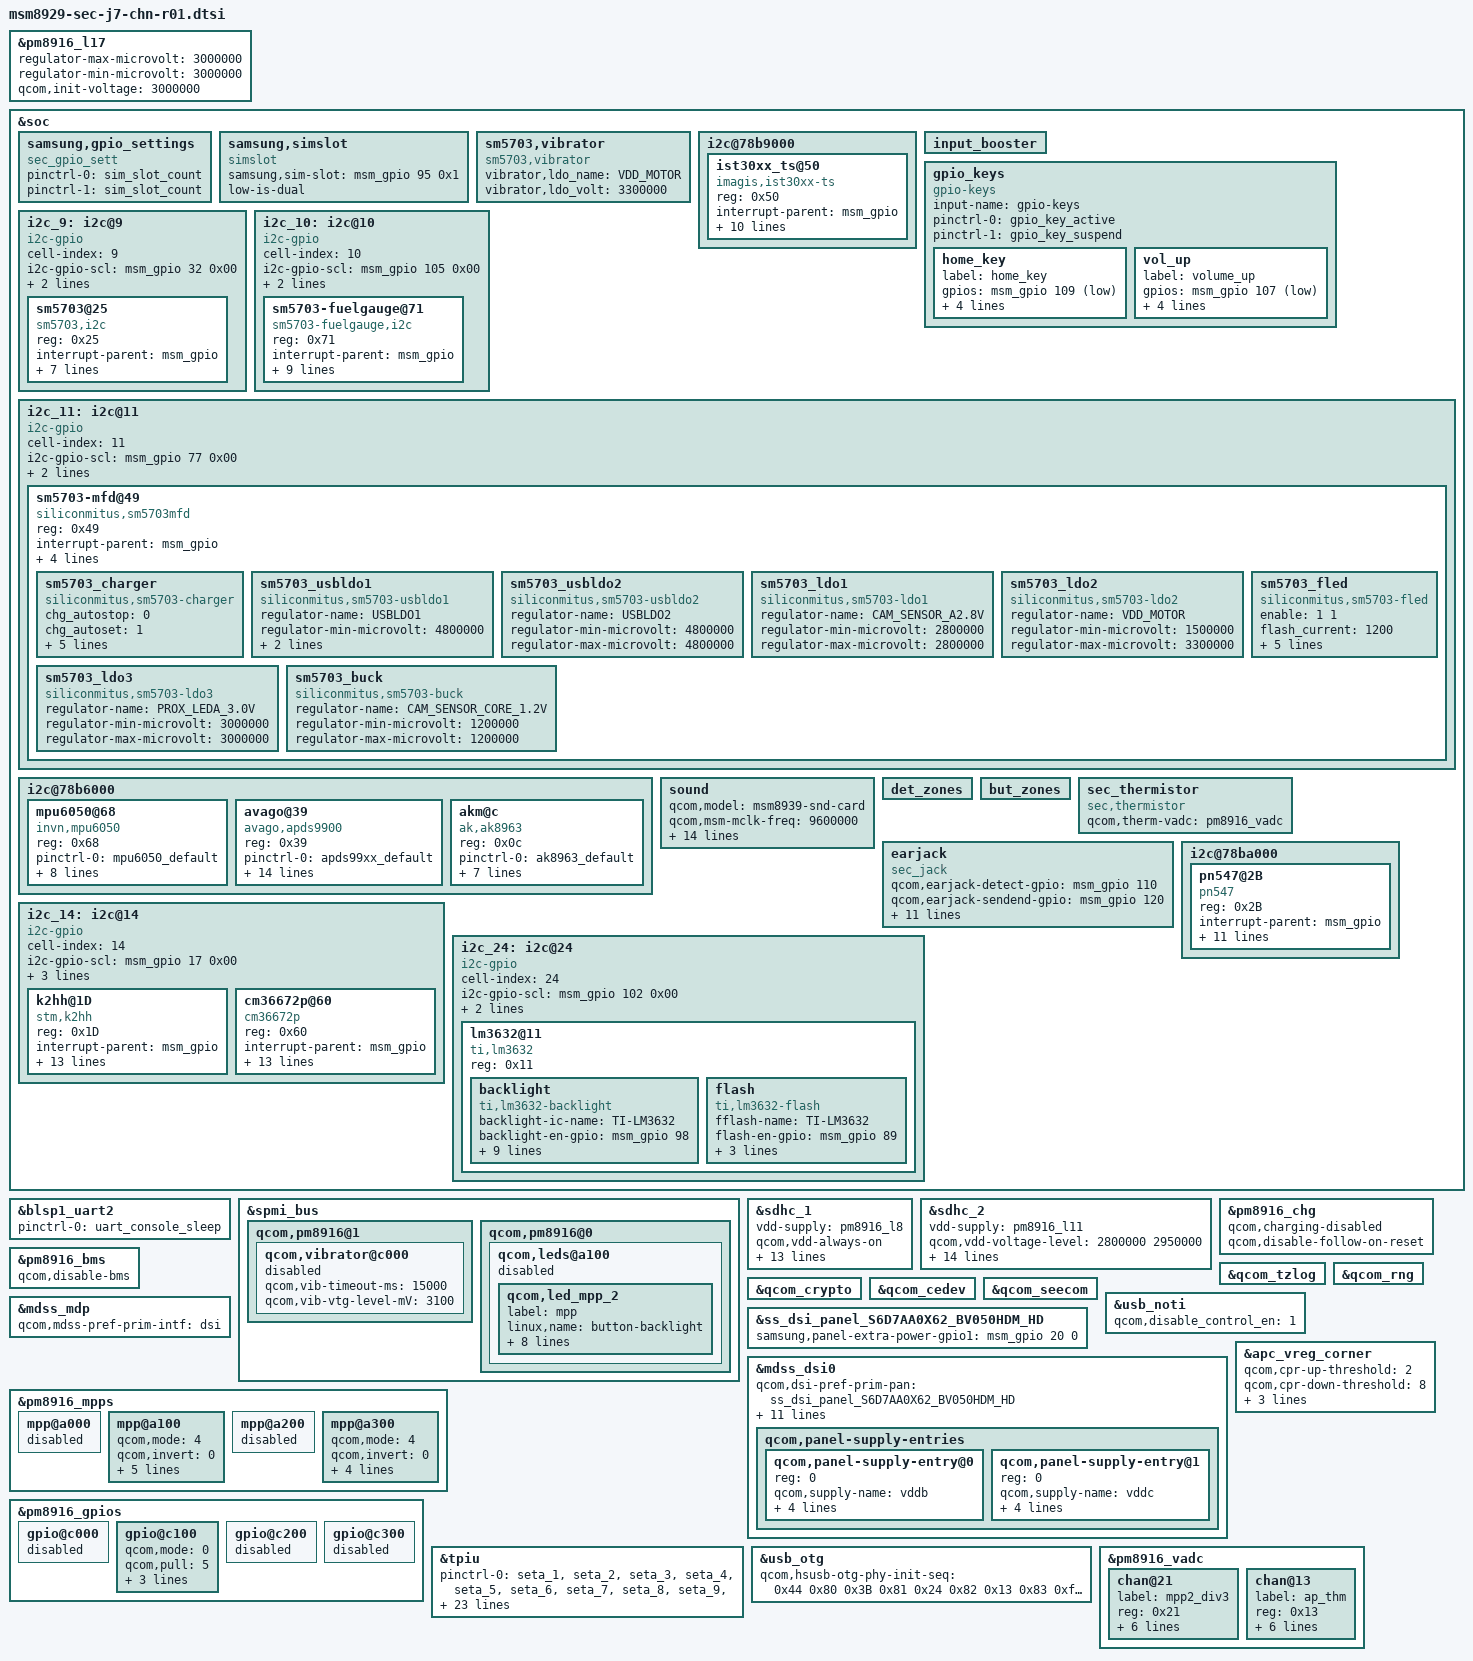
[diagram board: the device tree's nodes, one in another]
/*
 * Copyright (c) 2015, The Linux Foundation. All rights reserved.
 *
 * This program is free software; you can redistribute it and/or modify
 * it under the terms of the GNU General Public License version 2 and
 * only version 2 as published by the Free Software Foundation.
 *
 * This program is distributed in the hope that it will be useful,
 * but WITHOUT ANY WARRANTY; without even the implied warranty of
 * MERCHANTABILITY or FITNESS FOR A PARTICULAR PURPOSE.  See the
 * GNU General Public License for more details.
 */

#include "msm8929.dtsi"
#include "msm8929-pinctrl-sec-j7-chn-r01.dtsi"
#include "msm8939-mdss.dtsi"
#include "msm8929-sec-j7-battery-r00.dtsi"
#include "msm8939-audio-internal_codec.dtsi"
#include "../../../../../../drivers/video/msm/mdss/samsung/S6D7AA0X62_BV050HDM/dsi_panel_S6D7AA0X62_BV050HDM_hd_5_5_video.dtsi"
#include "msm8929-camera-sensor-cdp-j7-r00.dtsi"

&pm8916_l17 {
	regulator-max-microvolt = <3000000>;
	regulator-min-microvolt = <3000000>;
	qcom,init-voltage = <3000000>;
};

&soc {

	samsung,gpio_settings{
                compatible = "sec_gpio_sett";
                pinctrl-names = "sec_gpio_active","sec_gpio_suspend";
                pinctrl-0 = <&sim_slot_count>;
                pinctrl-1 = <&sim_slot_count>;
        };

	samsung,simslot {
        compatible = "simslot";
        samsung,sim-slot = <&msm_gpio 95 0x1>;
        low-is-dual; // If the value of sim-slot gpio is 'low' in 'dual sim' device, you must set this boolean property.
        status = "ok";
        };

	sm5703,vibrator {
		compatible = "sm5703,vibrator";
		vibrator,ldo_name = "VDD_MOTOR";
		vibrator,ldo_volt = <3300000>;
		status = "ok";
	};

	i2c@78b9000 { /* BLSP1 QUP5 */
		status = "okay";
		ist30xx_ts@50 {
			compatible = "imagis,ist30xx-ts";
			reg = <0x50>;
			interrupt-parent = <&msm_gpio>;
			interrupts = <13 0>;
			pinctrl-names = "active_state", "suspend_state";
			pinctrl-0 = <&ts_int_active &tsp_en_active>;
			pinctrl-1 = <&ts_int_suspend &tsp_en_suspend>;
			vdd_en-gpio = <&msm_gpio 73 0x01>;
			vdd_1p8-supply = <&pm8916_l6>;
			imagis,irq-gpio = <&msm_gpio 13 0x00>;
			imagis,i2c-pull-up = <1>;
			imagis,fw-bin = <1>;
			imagis,ic-version = "ist3038c";
			imagis,project-name = "j7";
		};
	};

	input_booster {
		status = "okay";
	};

	gpio_keys {
		compatible = "gpio-keys";
		input-name = "gpio-keys";
		pinctrl-names = "tlmm_gpio_key_active","tlmm_gpio_key_suspend";
		pinctrl-0 = <&gpio_key_active>;
		pinctrl-1 = <&gpio_key_suspend>;

		home_key {
			label = "home_key";
			gpios = <&msm_gpio 109 0x1>;
			linux,input-type = <1>;
			linux,code = <172>;
			gpio-key,wakeup;
			debounce-interval = <15>;
		};

		vol_up {
			label = "volume_up";
			gpios = <&msm_gpio 107 0x1>;
			linux,input-type = <1>;
			linux,code = <115>;
			gpio-key,wakeup;
			debounce-interval = <15>;
		};
	};

	i2c_9:i2c@9 { /*SM5703 GPIO-I2C*/
		cell-index = <9>;
		compatible = "i2c-gpio";
		i2c-gpio-scl = <&msm_gpio 32 0x00>;
		i2c-gpio-sda = <&msm_gpio 31 0x00>;
		i2c-gpio,delay-us = <2>;
		#address-cells = <1>;
		#size-cells = <0>;

		sm5703@25{
			compatible = "sm5703,i2c";
			reg = <0x25>;
			interrupt-parent = <&msm_gpio>;
			interrupts= <12 0>;
			sm5703,irq-gpio = <&msm_gpio 12 0x00>;
			sm5703,gpio-scl = <&msm_gpio 32 0x00>;
			sm5703,gpio-sda = <&msm_gpio 31 0x00>;
			sm5703,uarton-gpio = <&msm_gpio 114 0x00>;
			pinctrl-names = "sm5703_i2c_active","sm5703_i2c_suspend";
			pinctrl-0 = <&muic_i2c_active &muic_int_pin>;
			pinctrl-1 = <&muic_i2c_suspend &muic_int_pin>;
		};
	};

	i2c_10:i2c@10 {
		cell-index = <10>;
		compatible = "i2c-gpio";
		i2c-gpio-scl = <&msm_gpio 105 0x00>;
		i2c-gpio-sda = <&msm_gpio 106 0x00>;
		i2c-gpio,delay-us = <2>;
		#address-cells = <1>;
		#size-cells = <0>;

		sm5703-fuelgauge@71{
			compatible = "sm5703-fuelgauge,i2c";
			reg = <0x71>;
			interrupt-parent = <&msm_gpio>;
			pinctrl-names = "default";
			pinctrl-0 = <&fg_i2c_active &fuel_int_active>;
			fuelgauge,irqf = "IRQF_TRIGGER_FALLING + IRQF_ONESHOT + IRQF_NO_SUSPEND";
			fuelgauge,fuel_int = <&msm_gpio 121 0x1>;
			fuelgauge,capacity_max = <1000>;
			fuelgauge,capacity_max_margin = <50>;
			fuelgauge,capacity_min = <0>;
			fuelgauge,capacity_calculation_type = <0x17>;
			fuelgauge,fuel_alert_soc = <1>;
		};
	};

	i2c_11:i2c@11 {
		cell-index = <11>;
		compatible = "i2c-gpio";
		i2c-gpio-scl = <&msm_gpio 77 0x00>;
		i2c-gpio-sda = <&msm_gpio 76 0x00>;
		i2c-gpio,delay-us = <2>;
		#address-cells = <1>;
		#size-cells = <0>;

		sm5703-mfd@49{
			compatible = "siliconmitus,sm5703mfd";
			reg = <0x49>;
			interrupt-parent = <&msm_gpio>;
			sm5703,irq-gpio = <&msm_gpio 62 0x00>;
			pinctrl-names = "default";
			pinctrl-0 = <&chg_i2c_active &charger_int_active &if_pmic_rst_active &chg_en_active>;
			sm5703,mrstb-gpio = <&msm_gpio 108 0x00>;

			sm5703_charger {
				compatible = "siliconmitus,sm5703-charger";
				chg_autostop = <0>;
				chg_autoset = <1>;
				chg_aiclen = <1>;
				chg_aiclth = <4500>;
				fg_vol_val = <4350>;
				fg_soc_val = <95>;
				fg_curr_avr_val = <150>;
			};

			sm5703_usbldo1 {
				compatible = "siliconmitus,sm5703-usbldo1";
				regulator-name = "USBLDO1"; /* change name by yourself */
				regulator-min-microvolt = <4800000>;
				regulator-max-microvolt = <4800000>; /* max == min then apply_uV = 1 */
				/* regulator-microvolt-offset = < >; optional*/
				/* regulator-boot-on = "yes"; optional, exist = enabled */
				regulator-always-on = "yes";
				/* regulator-ramp-delay = <100>; optional*/

			};
			sm5703_usbldo2 {
				compatible = "siliconmitus,sm5703-usbldo2";
				regulator-name = "USBLDO2"; /* change name by yourself */
				regulator-min-microvolt = <4800000>;
				regulator-max-microvolt = <4800000>; /* max == min then apply_uV = 1 */
				/* regulator-microvolt-offset = < >; optional*/
				/* regulator-boot-on = "yes"; optional, exist = enabled */
				/* regulator-always-on = "yes"; optional, exist = enabled */
				/* regulator-ramp-delay = <100>; optional*/

			};
			sm5703_ldo1 {
				compatible = "siliconmitus,sm5703-ldo1";
				regulator-name = "CAM_SENSOR_A2.8V"; /* change name by yourself */
				regulator-min-microvolt = <2800000>;
				regulator-max-microvolt = <2800000>; /* max == min then apply_uV = 1 */
				/* regulator-microvolt-offset = < >; optional*/
				/* regulator-boot-on = "yes"; optional, exist = enabled */
				/* regulator-always-on = "yes"; optional, exist = enabled */
				/* regulator-ramp-delay = <100>; optional*/
			};

			sm5703_ldo2 {
				compatible = "siliconmitus,sm5703-ldo2";
				regulator-name = "VDD_MOTOR"; /* change name by yourself */
				regulator-min-microvolt = <1500000>;
				regulator-max-microvolt = <3300000>; /* max == min then apply_uV = 1 */
				/* regulator-microvolt-offset = < >; optional*/
				/* regulator-boot-on = "yes"; optional, exist = enabled */
				/* regulator-always-on = "yes"; optional, exist = enabled */
				/* regulator-ramp-delay = <100>; optional*/
			};

			sm5703_ldo3 {
				compatible = "siliconmitus,sm5703-ldo3";
				regulator-name = "PROX_LEDA_3.0V"; /* change name by yourself */
				regulator-min-microvolt = <3000000>;
				regulator-max-microvolt = <3000000>; /* max == min then apply_uV = 1 */
				/* regulator-microvolt-offset = < >; optional*/
				/* regulator-boot-on = "yes"; optional, exist = enabled */
				/* regulator-always-on = "yes"; optional, exist = enabled */
				/* regulator-ramp-delay = <100>; optional*/
			};

			sm5703_buck {
				compatible = "siliconmitus,sm5703-buck";
				regulator-name = "CAM_SENSOR_CORE_1.2V"; /* change name by yourself */
				regulator-min-microvolt = <1200000>;
				regulator-max-microvolt = <1200000>; /* max == min then apply_uV = 1 */
				/* regulator-microvolt-offset = < >; optional*/
				/* regulator-boot-on = "yes"; optional, exist = enabled */
				/* regulator-always-on = "yes"; optional, exist = enabled */
				/* regulator-ramp-delay = <100>; optional*/
			};

			sm5703_fled {
				compatible = "siliconmitus,sm5703-fled";
				enable = <1 1>;
				flash_current = <1200>;
				movie_current = <170>;
				sm5703,led1-gpio = <&msm_gpio 34 0x00>;
				sm5703,led2-gpio = <&msm_gpio 36 0x00>;
				pinctrl-names = "fled_default","fled_sleep";
				pinctrl-0 = <&cam_flash_active>;
				pinctrl-1 = <&cam_flash_sleep>;
			};
		};
	};

	i2c@78b6000 { /* BLSP1 QUP2 */
		mpu6050@68 { /* Gyroscope and accelerometer sensor combo */
			compatible = "invn,mpu6050";
			reg = <0x68>;
			pinctrl-names = "mpu_default","mpu_sleep";
			pinctrl-0 = <&mpu6050_default>;
			pinctrl-1 = <&mpu6050_sleep>;
			interrupt-parent = <&msm_gpio>;
			interrupts = <115 0x2>;
			vdd-supply = <&pm8916_l17>;
			vlogic-supply = <&pm8916_l16>;
			vi2c-supply = <&pm8916_l6>;
			invn,gpio-int = <&msm_gpio 115 0x2>;
			invn,place = "Portrait Down Back Side";
		};

		avago@39 { /* Ambient light and proximity sensor */
			compatible = "avago,apds9900";
			reg = <0x39>;
			pinctrl-names = "default","sleep";
			pinctrl-0 = <&apds99xx_default>;
			pinctrl-1 = <&apds99xx_sleep>;
			interrupt-parent = <&msm_gpio>;
			interrupts = <113 0x2002>;
			vdd-supply = <&pm8916_l17>;
			vio-supply = <&pm8916_l6>;
			avago,irq-gpio = <&msm_gpio 113 0x2002>;
			avago,ps-threshold = <600>;
			avago,ps-hysteresis-threshold = <500>;
			avago,ps-pulse = <8>;
			avago,ps-pgain = <0>;
			avago,als-B = <223>;
			avago,als-C = <70>;
			avago,als-D = <142>;
			avago,ga-value = <48>;
		};

		akm@c {
			compatible = "ak,ak8963";
			reg = <0x0c>;
			pinctrl-names = "ak8963_default", "ak8963_sleep";
			pinctrl-0 = <&ak8963_default>;
			pinctrl-1 = <&ak8963_sleep>;
			interrupt-parent = <&msm_gpio>;
			interrupts = <69 0x2>;
			vdd-supply = <&pm8916_l17>;
			vio-supply = <&pm8916_l6>;
			ak,layout = <0x6>;
			ak,auto-report;
		};

	};

	sound {
		qcom,model = "msm8939-snd-card";
/*		qcom,msm-ext-pa = "quaternary";*/
		qcom,msm-mclk-freq = <9600000>;
		qcom,audio-routing =
			"RX_BIAS", "MCLK",
			"SPK_RX_BIAS", "MCLK",
			"INT_LDO_H", "MCLK",
			"MIC BIAS External", "Handset Mic",
			"MIC BIAS External", "Secondary Mic",
			"AMIC1", "MIC BIAS External",
			"AMIC2", "Headset Mic",
			"AMIC3", "MIC BIAS External";
		pinctrl-names = "cdc_lines_act",
				"cdc_lines_sus",
				"cross_conn_det_act",
				"cross_conn_det_sus",
				"cdc_lines_quat_ext_act",
				"cdc_lines_quat_ext_sus";
		pinctrl-0 = <&cdc_pdm_lines_act>;
		pinctrl-1 = <&cdc_pdm_lines_sus>;
		pinctrl-2 = <&cross_conn_det_act>;
		pinctrl-3 = <&cross_conn_det_sus>;
		pinctrl-4 = <&cdc_pdm_lines_act &ext_cdc_tlmm_lines_act>;
		pinctrl-5 = <&cdc_pdm_lines_sus &ext_cdc_tlmm_lines_sus>;
	};

	det_zones: det_zones {
		#list-det-cells = <4>;
	};

	but_zones: but_zones {
		#list-but-cells = <3>;
	};

	sec_thermistor {
		compatible = "sec,thermistor";
		qcom,therm-vadc = <&pm8916_vadc>;
	};

	earjack {
		compatible = "sec_jack";
		qcom,earjack-detect-gpio = <&msm_gpio 110 0x0>;
		qcom,earjack-sendend-gpio = <&msm_gpio 120 0x0>;
		qcom,earjack-read-vadc = <&pm8916_vadc>;

		det-zones-list = <&det_zones 0 10000 10 0>,
						 <&det_zones 970 10000 10 0>,
						 <&det_zones 971 10000 10 1>,
						 <&det_zones 9999 10000 10 1>;
		but-zones-list = <&but_zones 0 0 302>,
						<&but_zones 3 303 349>,	
						 <&but_zones 1 350 462>,
						 <&but_zones 2 463 999>;
		mpp-channel-scaling = <2 1 3>;
		pinctrl-names = "earjack_gpio_active","earjack_gpio_suspend";
		pinctrl-0 = <&earjack_det_act &earjack_switch_act>;
		pinctrl-1 = <&earjack_det_sus &earjack_switch_sus>;
	};

	i2c_14:i2c@14 {
		cell-index = <14>;
		compatible = "i2c-gpio";
		i2c-gpio-scl = <&msm_gpio 17 0x00>;
		i2c-gpio-sda = <&msm_gpio 16 0x00>;
		i2c-gpio,delay-us = <2>;
		#address-cells = <1>;
		#size-cells = <0>;
		pinctrl-names = "default";
		pinctrl-0 = <&sensor_i2c_default>;
		k2hh@1D {
			compatible = "stm,k2hh";
			reg = <0x1D>;
			interrupt-parent = <&msm_gpio>;
			interrupts = <115 0>;
			pinctrl-names = "default";
			pinctrl-0 = <&acc_int_active>;
			stm,irq_gpio = <&msm_gpio 115 0x00>;
			stm,vio-supply = <&pm8916_l5>;
			stm,vdd-supply = <&pm8916_l17>;
			stm,axis_map_x = <0>;
			stm,axis_map_y = <1>;
			stm,axis_map_z = <2>;
			stm,negate_x = <0>;
			stm,negate_y = <0>;
			stm,negate_z = <1>;
			stm,poll_interval = <100>;
			stm,min_interval = <2>;
		};
		cm36672p@60 {
			compatible = "cm36672p";
			reg = <0x60>;
			interrupt-parent = <&msm_gpio>;
			interrupts = <113 0>;
			pinctrl-names = "default";
			pinctrl-0 = <&prox_int_active>;
			pinctrl-1 = <&prox_int_suspend>;
			cm36672p,irq_gpio = <&msm_gpio 113 0x1>;
			cm36672p,vdd-supply = <&pm8916_l17>;
			cm36672p,vio-supply = <&pm8916_l5>;
			cm36672p,default_hi_thd = <17>;
			cm36672p,default_low_thd = <13>;
			cm36672p,cancel_hi_thd = <10>;
			cm36672p,cancel_low_thd = <7>;
			cm36672p,ps_it = <4>;
			cm36672p,led_current = <5>;
			cm36672p,default_trim = <0>;
		};
	};
};

&blsp1_uart2 {
	status = "ok";
	pinctrl-names = "default";
	pinctrl-0 = <&uart_console_sleep>;
};

&spmi_bus {
	qcom,pm8916@1 {
		qcom,vibrator@c000 {
			status = "disabled";
			qcom,vib-timeout-ms = <15000>;
			qcom,vib-vtg-level-mV = <3100>;
		};
	};

	qcom,pm8916@0 {
		qcom,leds@a100 {
			status = "disabled";
			qcom,led_mpp_2 {
				label = "mpp";
				linux,name = "button-backlight";
				linux,default-trigger = "none";
				qcom,default-state = "off";
				qcom,max-current = <40>;
				qcom,current-setting = <5>;
				qcom,id = <6>;
				qcom,mode = "manual";
				qcom,source-sel = <1>;
				qcom,mode-ctrl = <0x60>;
			};
		};
	};
};

&sdhc_1 {
	vdd-supply = <&pm8916_l8>;
	qcom,vdd-always-on;
	qcom,vdd-lpm-sup;
	qcom,vdd-voltage-level = <2900000 2900000>;
	qcom,vdd-current-level = <200 400000>;

	vdd-io-supply = <&pm8916_l5>;
	qcom,vdd-io-always-on;
	qcom,vdd-io-lpm-sup;
	qcom,vdd-io-voltage-level = <1800000 1800000>;
	qcom,vdd-io-current-level = <200 60000>;

	pinctrl-names = "active", "sleep";
	pinctrl-0 = <&sdc1_clk_on &sdc1_cmd_on &sdc1_data_on>;
	pinctrl-1 = <&sdc1_clk_off &sdc1_cmd_off &sdc1_data_off>;

	qcom,nonremovable;

	status = "ok";
};

&sdhc_2 {
	vdd-supply = <&pm8916_l11>;
	qcom,vdd-voltage-level = <2800000 2950000>;
	qcom,vdd-current-level = <15000 400000>;

	vdd-io-supply = <&pm8916_l12>;
	qcom,vdd-io-voltage-level = <1800000 2950000>;
	qcom,vdd-io-current-level = <200 50000>;

	pinctrl-names = "active", "sleep";
	pinctrl-0 = <&sdc2_clk_on &sdc2_cmd_on &sdc2_data_on &sdc2_cd_on>;
	pinctrl-1 = <&sdc2_clk_off &sdc2_cmd_off &sdc2_data_off &sdc2_cd_off>;

	#address-cells = <0>;
	interrupt-parent = <&sdhc_2>;
	interrupts = <0 1 2>;
	#interrupt-cells = <1>;
	interrupt-map-mask = <0xffffffff>;
	interrupt-map = <0 &intc 0 125 0
			1 &intc 0 221 0
			2 &msm_gpio 38 0>;
	interrupt-names = "hc_irq", "pwr_irq", "status_irq";
	cd-gpios = <&msm_gpio 38 0x1>;

	status = "ok";
};

&pm8916_chg {
	status = "ok";
	qcom,charging-disabled;
	qcom,disable-follow-on-reset;
};

&pm8916_bms {
	status = "ok";
	qcom,disable-bms;
};

&qcom_tzlog {
	status = "okay";
};

&qcom_rng {
	status = "okay";
};

&qcom_crypto {
	status = "okay";
};

&qcom_cedev {
	status = "okay";
};

&qcom_seecom {
	status = "okay";
};

&usb_noti {
	qcom,disable_control_en = <1>;
};

&mdss_mdp {
       qcom,mdss-pref-prim-intf = "dsi";
};

&ss_dsi_panel_S6D7AA0X62_BV050HDM_HD{
	samsung,panel-extra-power-gpio1 = <&msm_gpio 20 0>;
};

&mdss_dsi0 {
	qcom,dsi-pref-prim-pan = <&ss_dsi_panel_S6D7AA0X62_BV050HDM_HD>;
	pinctrl-names = "mdss_default", "mdss_sleep";
	pinctrl-0 = <&mdss_dsi_active &lcd_esd_det_active &bl_active &bl_i2c_active>;
	pinctrl-1 = <&mdss_dsi_suspend &lcd_esd_det_suspend &bl_suspend &bl_i2c_suspend>;
	qcom,platform-reset-gpio = <&msm_gpio 25 0>;
	gdsc-supply = <&gdsc_mdss>;
	vddb-supply = <&pm8916_s4>;
	vddc-supply = <&pm8916_l5>;
	qcom,platform-lane-config = [00 00 00 00 00 00 00 01 97
		00 00 00 00 05 00 00 01 97
		00 00 00 00 0a 00 00 01 97
		00 00 00 00 0f 00 00 01 97
		00 c0 00 00 00 00 00 01 bb];
	qcom,panel-supply-entries {
		#address-cells = <1>;
		#size-cells = <0>;

		qcom,panel-supply-entry@0 {
			reg = <0>;
			qcom,supply-name = "vddb";
			qcom,supply-min-voltage = <2100000>;
			qcom,supply-max-voltage = <2100000>;
			qcom,supply-enable-load = <100000>;
			qcom,supply-disable-load = <100>;
		};
		qcom,panel-supply-entry@1 {
			reg = <0>;
			qcom,supply-name = "vddc";
			qcom,supply-min-voltage = <1800000>;
			qcom,supply-max-voltage = <1800000>;
			qcom,supply-enable-load = <100000>;
			qcom,supply-disable-load = <100>;
		};
	};
};

&pm8916_mpps {
	mpp@a000 { /* MPP 1 */
		/* VDD_PX */
		status = "disabled";
	};

	mpp@a100 { /* MPP 2 */
		status = "ok";
		qcom,mode = <4>; // AIN input
		qcom,invert = <0>; //No Invert
		qcom,output-type = <0>; //CMOS
		qcom,vin-sel = <2>; //PM8971_S3 1.8v
		qcom,src-sel = <0>; //MPP Constant
		qcom,ain-route = <1>; // QPNP_PIN_AIN_AMUX_CH6 = 1 for MPP2
		qcom,master-en = <1>; // Function constant
	};

	mpp@a200 { /* MPP 3 */
		/* VREF DAC */
		status = "disabled";
	};

	mpp@a300 { /* MPP 4 */
		status = "ok";
		qcom,mode = <4>;	/* AIN input */
		qcom,invert = <0>;	/* No Invert */
		qcom,output-type = <0>;	/* CMOS */
		qcom,src-sel = <0>;	/* MPP Constant */
		qcom,ain-route = <3>;	/* QPNP_PIN_AIN_AMUX_CH8 = 3 for MPP4 */
		qcom,master-en = <1>;	/* Function constant */
	};
};

&pm8916_gpios {
	gpio@c000 { /* GPIO 1 */
		/* Battery UICC Alarm */
		status = "disabled";
	};

	gpio@c100 { /* GPIO 2 */
		/* NFC_CLK_REQ */
		qcom,mode = <0>; /* QPNP_PIN_MODE_DIG_IN */
		qcom,pull = <5>; /* QPNP_PIN_PULL_NO */
		qcom,vin-sel = <2>; /* QPNP_PIN_VIN2 */
		qcom,src-sel = <2>; /* QPNP_PIN_SEL_FUNC_1 */
		qcom,master-en = <1>;
	};

	gpio@c200 { /* GPIO 3 */
		/* External regulator control for WTR */
		status = "disabled";
	};

	gpio@c300 { /* GPIO 4 */
		/* External regulator control for APC */
		status = "disabled";
	};
};

/* CoreSight */
&tpiu {
	pinctrl-names = "seta-pctrl", "setb-pctrl", "sdcard", "trace",
			"swduart", "swdtrc", "jtag", "spmi";
	/* Mictor */
	pinctrl-0 = <&seta_1 &seta_2 &seta_3 &seta_4 &seta_5 &seta_6 &seta_7
		     &seta_8 &seta_9 &seta_10 &seta_11 &seta_12 &seta_13
		     &seta_14 &seta_15 &seta_16 &seta_17 &seta_18>;
	pinctrl-1 = <&setb_1 &setb_2 &setb_3 &setb_4 &setb_5 &setb_6 &setb_7
		     &setb_8 &setb_9 &setb_10 &setb_11 &setb_12 &setb_13
		     &setb_14 &setb_15 &setb_16 &setb_17 &setb_18>;
	/* NIDnT */
	pinctrl-2 = <&qdsd_clk_sdcard &qdsd_cmd_sdcard
		    &qdsd_data0_sdcard &qdsd_data1_sdcard
		    &qdsd_data2_sdcard &qdsd_data3_sdcard>;
	pinctrl-3 = <&qdsd_clk_trace &qdsd_cmd_trace
		    &qdsd_data0_trace &qdsd_data1_trace
		    &qdsd_data2_trace &qdsd_data3_trace>;
	pinctrl-4 = <&qdsd_cmd_swduart &qdsd_data0_swduart
		    &qdsd_data1_swduart &qdsd_data2_swduart
		    &qdsd_data3_swduart>;
	pinctrl-5 = <&qdsd_clk_swdtrc &qdsd_cmd_swdtrc
		    &qdsd_data0_swdtrc &qdsd_data1_swdtrc
		    &qdsd_data2_swdtrc &qdsd_data3_swdtrc>;
	pinctrl-6 = <&qdsd_cmd_jtag &qdsd_data0_jtag
		    &qdsd_data1_jtag &qdsd_data2_jtag
		    &qdsd_data3_jtag>;
	pinctrl-7 = <&qdsd_clk_spmi &qdsd_cmd_spmi
		    &qdsd_data0_spmi &qdsd_data3_spmi>;
};

&apc_vreg_corner {
		qcom,cpr-up-threshold = <0>;
		qcom,cpr-down-threshold = <8>;
};

&usb_otg {
        qcom,hsusb-otg-phy-init-seq =
                        <0x44 0x80 0x3B 0x81 0x24 0x82 0x13 0x83 0xffffffff>;
};

&pm8916_vadc {
	chan@21 {
		label = "mpp2_div3";
		reg = <0x21>; // channel for MPP2 , 1:3scale
		qcom,decimation = <0>;
		qcom,pre-div-channel-scaling = <1>; // 1:3scale
		qcom,calibration-type = "absolute";
		qcom,scale-function = <0>;
		qcom,hw-settle-time = <1>;
		qcom,fast-avg-setup = <0>;
	};
};

&soc {
	i2c_24: i2c@24 {

		cell-index = <24>;
		compatible = "i2c-gpio";
		i2c-gpio-scl = <&msm_gpio 102  0x00>; /*scl gpio*/
		i2c-gpio-sda = <&msm_gpio 101 0x00>;  /*sda gpio*/
		i2c-gpio,delay-us = <4>;
		lm3632@11 {
			compatible = "ti,lm3632";
			reg = <0x11>;
			backlight{
				compatible = "ti,lm3632-backlight";
				backlight-ic-name = "TI-LM3632";
				backlight-en-gpio = <&msm_gpio 98 0x00>;
				backlight-panel-enp-gpio = <&msm_gpio 50 0x00>;
				backlight-panel-enn-gpio = <&msm_gpio 51 0x00>;
				backlight-ic-tuning = [
					09	41
					02	50
					03	0D
					04	05
					0A	19
					05	CC
					0D	1E
					0E	1E
					0F	1E
					0C	1F
				];
				backlight-ic-tuning-outdoor = [
					09	01
					04	06
					05	D1
				];
				backlight-ic-tuning-normal = [
					04	05
					05	CC
					09	41
				];
				backlight-i2c-bl-control = [
					04      00
					05      00
				];
			};
			flash{
				compatible = "ti,lm3632-flash";
				fflash-name = "TI-LM3632";
				flash-en-gpio = <&msm_gpio 89 0x00>;
				flash-int-gpio = <&msm_gpio 90 0x00>;
				pinctrl-names = "front_fled_default","front_fled_sleep";
				pinctrl-0 = <&front_flash_active>;
				pinctrl-1 = <&front_flash_sleep>;
			};
		};
	};
};

&apc_vreg_corner {
	vdd-apc-supply = <&fan53555>;
	qcom,cpr-step-quotient = <26>;
	qcom,cpr-apc-volt-step = <12500>;
	qcom,cpr-up-threshold = <2>;
};

&soc {
	i2c@78ba000 { /* BLSP1 QUP6 */
		status = "ok";
		pn547@2B {
			compatible = "pn547";
			reg = <0x2B>;
			interrupt-parent = <&msm_gpio>;
			interrupts = <21 0>;
			pinctrl-names = "nfc_active","nfc_suspend";
			pinctrl-0 = <&nfc_int_active &nfc_enable_active &nfc_firmware_active>;
			pinctrl-1 = <&nfc_int_suspend &nfc_enable_suspend &nfc_firmware_suspend>;
			pn547,firm-gpio = <&msm_gpio 49 0x00>;
			pn547,ven-gpio = <&msm_gpio 116 0x00>;
			pn547,irq-gpio = <&msm_gpio 21 0x01>;
			nfc_ldo-supply = <&pm8916_l14>;
			qcom,clk-src = "BBCLK2";
			clocks = <&clock_rpm clk_bb_clk2_pin>;
			clock-names = "nfc_clock";
		};
	};
};
&pm8916_vadc {
	chan@13 {
		label = "ap_thm";
		reg = <0x13>;	/* channel 19 for MPP4 , 1:1scale */
		qcom,decimation = <0>;
		qcom,pre-div-channel-scaling = <0>;	/* 1:1scale */
		qcom,calibration-type = "ratiometric";
		qcom,scale-function = <1>;
		qcom,hw-settle-time = <2>;
		qcom,fast-avg-setup = <0>;
	};
};
